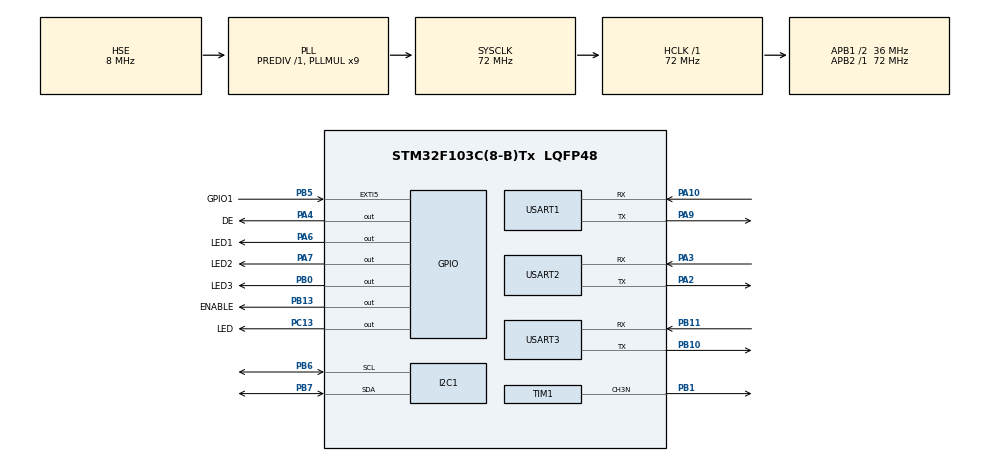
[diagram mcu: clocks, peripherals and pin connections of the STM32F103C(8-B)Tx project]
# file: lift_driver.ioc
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I2C1.DutyCycle=I2C_DUTYCYCLE_16_9
I2C1.I2C_Mode=I2C_Fast
Mcu.Family=STM32F1
Mcu.Name=STM32F103C(8-B)Tx
Mcu.Package=LQFP48
NVIC.EXTI9_5_IRQn=true\:0\:0\:false\:false\:true\:true\:true
NVIC.PriorityGroup=NVIC_PRIORITYGROUP_4
NVIC.TIM3_IRQn=true\:0\:0\:false\:false\:true\:true\:true
PA10.Mode=Asynchronous
PA10.Signal=USART1_RX
PA13.Mode=Serial_Wire
PA13.Signal=SYS_JTMS-SWDIO
PA14.Mode=Serial_Wire
PA14.Signal=SYS_JTCK-SWCLK
PA2.Mode=Asynchronous
PA2.Signal=USART2_TX
PA3.Mode=Asynchronous
PA3.Signal=USART2_RX
PA4.GPIO_Label=DE
PA4.Signal=GPIO_Output
PA6.GPIO_Label=LED1
PA6.Signal=GPIO_Output
PA7.GPIO_Label=LED2
PA7.Signal=GPIO_Output
PA9.Mode=Asynchronous
PA9.Signal=USART1_TX
PB0.GPIO_Label=LED3
PB0.Signal=GPIO_Output
PB1.Mode=PWM Generation3 CH3N
PB1.Signal=TIM1_CH3N
PB10.Mode=Asynchronous
PB10.Signal=USART3_TX
PB11.Mode=Asynchronous
PB11.Signal=USART3_RX
PB13.GPIO_Label=ENABLE
PB13.Signal=GPIO_Output
PB5.GPIO_Label=GPIO1
PB5.GPIO_ModeDefaultEXTI=GPIO_MODE_IT_FALLING
PB5.GPIO_PuPd=GPIO_PULLUP
PB5.Signal=GPXTI5
PB6.Mode=I2C
PB6.Signal=I2C1_SCL
PB7.Mode=I2C
PB7.Signal=I2C1_SDA
PC13-TAMPER-RTC.GPIO_Label=LED
PC13-TAMPER-RTC.Signal=GPIO_Output
PD0-OSC_IN.Mode=HSE-External-Oscillator
PD0-OSC_IN.Signal=RCC_OSC_IN
PD1-OSC_OUT.Mode=HSE-External-Oscillator
PD1-OSC_OUT.Signal=RCC_OSC_OUT
ProjectManager.HeapSize=0x200
ProjectManager.StackSize=0x400
ProjectManager.TargetToolchain=Makefile
RCC.AHBFreq_Value=72000000
RCC.APB1CLKDivider=RCC_HCLK_DIV2
RCC.APB1Freq_Value=36000000
RCC.APB1TimFreq_Value=72000000
RCC.APB2Freq_Value=72000000
RCC.APB2TimFreq_Value=72000000
RCC.HCLKFreq_Value=72000000
RCC.PLLMUL=RCC_PLL_MUL9
RCC.PLLSourceVirtual=RCC_PLLSOURCE_HSE
RCC.SYSCLKFreq_VALUE=72000000
RCC.SYSCLKSource=RCC_SYSCLKSOURCE_PLLCLK
RCC.USBFreq_Value=72000000
TIM1.Channel-PWM\ Generation3\ CH3N=TIM_CHANNEL_3
TIM1.Period=500
TIM1.Prescaler=100
TIM1.Pulse-PWM\ Generation3\ CH3N=250
TIM1.TIM_MasterOutputTrigger=TIM_TRGO_UPDATE
TIM1.TIM_MasterSlaveMode=TIM_MASTERSLAVEMODE_ENABLE
TIM3.Period=2000
TIM3.Prescaler=1
USART1.VirtualMode=VM_ASYNC
USART2.VirtualMode=VM_ASYNC
USART3.VirtualMode=VM_ASYNC
VP_TIM3_VS_ClockSourceITR.Mode=TriggerSource_ITR0
VP_TIM3_VS_ControllerModeClock.Mode=Clock Mode
board=custom

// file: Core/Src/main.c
/* USER CODE BEGIN Header */
/**
  ******************************************************************************
  * @file           : main.c
  * @brief          : Main program body
  ******************************************************************************
  * @attention
  *
  * <h2><center>&copy; Copyright (c) 2021 STMicroelectronics.
  * All rights reserved.</center></h2>
  *
  * This software component is licensed by ST under BSD 3-Clause license,
  * the "License"; You may not use this file except in compliance with the
  * License. You may obtain a copy of the License at:
  *                        opensource.org/licenses/BSD-3-Clause
  *
  ******************************************************************************
  */
/* USER CODE END Header */
#include "main.h"

I2C_HandleTypeDef hi2c1;

TIM_HandleTypeDef htim1;
TIM_HandleTypeDef htim3;

UART_HandleTypeDef huart1;
UART_HandleTypeDef huart2;
UART_HandleTypeDef huart3;

void SystemClock_Config(void);
static void MX_GPIO_Init(void);
static void MX_USART1_UART_Init(void);
static void MX_USART3_UART_Init(void);
static void MX_I2C1_Init(void);
static void MX_USART2_UART_Init(void);
static void MX_TIM1_Init(void);
static void MX_TIM3_Init(void);

/* USER CODE BEGIN 0 */
int myMain();
/* USER CODE END 0 */

int main(void)
{

  /* MCU Configuration--------------------------------------------------------*/

  /* Reset of all peripherals, Initializes the Flash interface and the Systick. */
  HAL_Init();

  /* Configure the system clock */
  SystemClock_Config();

  /* Initialize all configured peripherals */
  MX_GPIO_Init();
  MX_USART1_UART_Init();
  MX_USART3_UART_Init();
  MX_I2C1_Init();
  MX_USART2_UART_Init();
  MX_TIM1_Init();
  MX_TIM3_Init();
  /* USER CODE BEGIN 2 */
  myMain();

//    HAL_GPIO_TogglePin(LED_GPIO_Port, LED_Pin);
//    HAL_GPIO_TogglePin(LED1_GPIO_Port, LED1_Pin);
//    HAL_GPIO_TogglePin(LED2_GPIO_Port, LED2_Pin);
//    HAL_GPIO_TogglePin(LED3_GPIO_Port, LED3_Pin);
//    uint8_t k [5] = {'0', '1','2', '3', '4'};
//    HAL_UART_Init(&huart1);
  /* USER CODE END 2 */

  /* Infinite loop */
  while (1)
  {

    /* USER CODE BEGIN 3 */
//    HAL_Delay(100);
//      HAL_GPIO_TogglePin(LED_GPIO_Port, LED_Pin);

//       HAL_UART_Transmit(&huart1, k, 5, 100);
  }
  /* USER CODE END 3 */
}

void SystemClock_Config(void)
{
  RCC_OscInitTypeDef RCC_OscInitStruct = {0};
  RCC_ClkInitTypeDef RCC_ClkInitStruct = {0};

  /** Initializes the RCC Oscillators according to the specified parameters
  * in the RCC_OscInitTypeDef structure.
  */
  RCC_OscInitStruct.OscillatorType = RCC_OSCILLATORTYPE_HSE;
  RCC_OscInitStruct.HSEState = RCC_HSE_ON;
  RCC_OscInitStruct.HSEPredivValue = RCC_HSE_PREDIV_DIV1;
  RCC_OscInitStruct.HSIState = RCC_HSI_ON;
  RCC_OscInitStruct.PLL.PLLState = RCC_PLL_ON;
  RCC_OscInitStruct.PLL.PLLSource = RCC_PLLSOURCE_HSE;
  RCC_OscInitStruct.PLL.PLLMUL = RCC_PLL_MUL9;
  if (HAL_RCC_OscConfig(&RCC_OscInitStruct) != HAL_OK)
  {
    Error_Handler();
  }
  /** Initializes the CPU, AHB and APB buses clocks
  */
  RCC_ClkInitStruct.ClockType = RCC_CLOCKTYPE_HCLK|RCC_CLOCKTYPE_SYSCLK
                              |RCC_CLOCKTYPE_PCLK1|RCC_CLOCKTYPE_PCLK2;
  RCC_ClkInitStruct.SYSCLKSource = RCC_SYSCLKSOURCE_PLLCLK;
  RCC_ClkInitStruct.AHBCLKDivider = RCC_SYSCLK_DIV1;
  RCC_ClkInitStruct.APB1CLKDivider = RCC_HCLK_DIV2;
  RCC_ClkInitStruct.APB2CLKDivider = RCC_HCLK_DIV1;

  if (HAL_RCC_ClockConfig(&RCC_ClkInitStruct, FLASH_LATENCY_2) != HAL_OK)
  {
    Error_Handler();
  }
}

static void MX_I2C1_Init(void)
{

  hi2c1.Instance = I2C1;
  hi2c1.Init.ClockSpeed = 400000;
  hi2c1.Init.DutyCycle = I2C_DUTYCYCLE_16_9;
  hi2c1.Init.OwnAddress1 = 0;
  hi2c1.Init.AddressingMode = I2C_ADDRESSINGMODE_7BIT;
  hi2c1.Init.DualAddressMode = I2C_DUALADDRESS_DISABLE;
  hi2c1.Init.OwnAddress2 = 0;
  hi2c1.Init.GeneralCallMode = I2C_GENERALCALL_DISABLE;
  hi2c1.Init.NoStretchMode = I2C_NOSTRETCH_DISABLE;
  if (HAL_I2C_Init(&hi2c1) != HAL_OK)
  {
    Error_Handler();
  }

}

static void MX_TIM1_Init(void)
{

  TIM_MasterConfigTypeDef sMasterConfig = {0};
  TIM_OC_InitTypeDef sConfigOC = {0};
  TIM_BreakDeadTimeConfigTypeDef sBreakDeadTimeConfig = {0};

  htim1.Instance = TIM1;
  htim1.Init.Prescaler = 100;
  htim1.Init.CounterMode = TIM_COUNTERMODE_UP;
  htim1.Init.Period = 500;
  htim1.Init.ClockDivision = TIM_CLOCKDIVISION_DIV1;
  htim1.Init.RepetitionCounter = 0;
  htim1.Init.AutoReloadPreload = TIM_AUTORELOAD_PRELOAD_DISABLE;
  if (HAL_TIM_PWM_Init(&htim1) != HAL_OK)
  {
    Error_Handler();
  }
  sMasterConfig.MasterOutputTrigger = TIM_TRGO_UPDATE;
  sMasterConfig.MasterSlaveMode = TIM_MASTERSLAVEMODE_ENABLE;
  if (HAL_TIMEx_MasterConfigSynchronization(&htim1, &sMasterConfig) != HAL_OK)
  {
    Error_Handler();
  }
  sConfigOC.OCMode = TIM_OCMODE_PWM1;
  sConfigOC.Pulse = 250;
  sConfigOC.OCPolarity = TIM_OCPOLARITY_HIGH;
  sConfigOC.OCNPolarity = TIM_OCNPOLARITY_HIGH;
  sConfigOC.OCFastMode = TIM_OCFAST_DISABLE;
  sConfigOC.OCIdleState = TIM_OCIDLESTATE_RESET;
  sConfigOC.OCNIdleState = TIM_OCNIDLESTATE_RESET;
  if (HAL_TIM_PWM_ConfigChannel(&htim1, &sConfigOC, TIM_CHANNEL_3) != HAL_OK)
  {
    Error_Handler();
  }
  sBreakDeadTimeConfig.OffStateRunMode = TIM_OSSR_DISABLE;
  sBreakDeadTimeConfig.OffStateIDLEMode = TIM_OSSI_DISABLE;
  sBreakDeadTimeConfig.LockLevel = TIM_LOCKLEVEL_OFF;
  sBreakDeadTimeConfig.DeadTime = 0;
  sBreakDeadTimeConfig.BreakState = TIM_BREAK_DISABLE;
  sBreakDeadTimeConfig.BreakPolarity = TIM_BREAKPOLARITY_HIGH;
  sBreakDeadTimeConfig.AutomaticOutput = TIM_AUTOMATICOUTPUT_DISABLE;
  if (HAL_TIMEx_ConfigBreakDeadTime(&htim1, &sBreakDeadTimeConfig) != HAL_OK)
  {
    Error_Handler();
  }
  HAL_TIM_MspPostInit(&htim1);

}

static void MX_TIM3_Init(void)
{

  TIM_SlaveConfigTypeDef sSlaveConfig = {0};
  TIM_MasterConfigTypeDef sMasterConfig = {0};

  htim3.Instance = TIM3;
  htim3.Init.Prescaler = 1;
  htim3.Init.CounterMode = TIM_COUNTERMODE_UP;
  htim3.Init.Period = 2000;
  htim3.Init.ClockDivision = TIM_CLOCKDIVISION_DIV1;
  htim3.Init.AutoReloadPreload = TIM_AUTORELOAD_PRELOAD_DISABLE;
  if (HAL_TIM_Base_Init(&htim3) != HAL_OK)
  {
    Error_Handler();
  }
  sSlaveConfig.SlaveMode = TIM_SLAVEMODE_EXTERNAL1;
  sSlaveConfig.InputTrigger = TIM_TS_ITR0;
  if (HAL_TIM_SlaveConfigSynchro(&htim3, &sSlaveConfig) != HAL_OK)
  {
    Error_Handler();
  }
  sMasterConfig.MasterOutputTrigger = TIM_TRGO_RESET;
  sMasterConfig.MasterSlaveMode = TIM_MASTERSLAVEMODE_DISABLE;
  if (HAL_TIMEx_MasterConfigSynchronization(&htim3, &sMasterConfig) != HAL_OK)
  {
    Error_Handler();
  }

}

static void MX_USART1_UART_Init(void)
{

  huart1.Instance = USART1;
  huart1.Init.BaudRate = 115200;
  huart1.Init.WordLength = UART_WORDLENGTH_8B;
  huart1.Init.StopBits = UART_STOPBITS_1;
  huart1.Init.Parity = UART_PARITY_NONE;
  huart1.Init.Mode = UART_MODE_TX_RX;
  huart1.Init.HwFlowCtl = UART_HWCONTROL_NONE;
  huart1.Init.OverSampling = UART_OVERSAMPLING_16;
  if (HAL_UART_Init(&huart1) != HAL_OK)
  {
    Error_Handler();
  }

}

static void MX_USART2_UART_Init(void)
{

  huart2.Instance = USART2;
  huart2.Init.BaudRate = 115200;
  huart2.Init.WordLength = UART_WORDLENGTH_8B;
  huart2.Init.StopBits = UART_STOPBITS_1;
  huart2.Init.Parity = UART_PARITY_NONE;
  huart2.Init.Mode = UART_MODE_TX_RX;
  huart2.Init.HwFlowCtl = UART_HWCONTROL_NONE;
  huart2.Init.OverSampling = UART_OVERSAMPLING_16;
  if (HAL_UART_Init(&huart2) != HAL_OK)
  {
    Error_Handler();
  }

}

static void MX_USART3_UART_Init(void)
{

  huart3.Instance = USART3;
  huart3.Init.BaudRate = 115200;
  huart3.Init.WordLength = UART_WORDLENGTH_8B;
  huart3.Init.StopBits = UART_STOPBITS_1;
  huart3.Init.Parity = UART_PARITY_NONE;
  huart3.Init.Mode = UART_MODE_TX_RX;
  huart3.Init.HwFlowCtl = UART_HWCONTROL_NONE;
  huart3.Init.OverSampling = UART_OVERSAMPLING_16;
  if (HAL_UART_Init(&huart3) != HAL_OK)
  {
    Error_Handler();
  }

}

static void MX_GPIO_Init(void)
{
  GPIO_InitTypeDef GPIO_InitStruct = {0};

  /* GPIO Ports Clock Enable */
  __HAL_RCC_GPIOC_CLK_ENABLE();
  __HAL_RCC_GPIOD_CLK_ENABLE();
  __HAL_RCC_GPIOA_CLK_ENABLE();
  __HAL_RCC_GPIOB_CLK_ENABLE();

  /*Configure GPIO pin Output Level */
  HAL_GPIO_WritePin(LED_GPIO_Port, LED_Pin, GPIO_PIN_RESET);

  /*Configure GPIO pin Output Level */
  HAL_GPIO_WritePin(GPIOA, DE_Pin|LED1_Pin|LED2_Pin, GPIO_PIN_RESET);

  /*Configure GPIO pin Output Level */
  HAL_GPIO_WritePin(GPIOB, LED3_Pin|ENABLE_Pin, GPIO_PIN_RESET);

  /*Configure GPIO pin : LED_Pin */
  GPIO_InitStruct.Pin = LED_Pin;
  GPIO_InitStruct.Mode = GPIO_MODE_OUTPUT_PP;
  GPIO_InitStruct.Pull = GPIO_NOPULL;
  GPIO_InitStruct.Speed = GPIO_SPEED_FREQ_LOW;
  HAL_GPIO_Init(LED_GPIO_Port, &GPIO_InitStruct);

  /*Configure GPIO pins : DE_Pin LED1_Pin LED2_Pin */
  GPIO_InitStruct.Pin = DE_Pin|LED1_Pin|LED2_Pin;
  GPIO_InitStruct.Mode = GPIO_MODE_OUTPUT_PP;
  GPIO_InitStruct.Pull = GPIO_NOPULL;
  GPIO_InitStruct.Speed = GPIO_SPEED_FREQ_LOW;
  HAL_GPIO_Init(GPIOA, &GPIO_InitStruct);

  /*Configure GPIO pins : LED3_Pin ENABLE_Pin */
  GPIO_InitStruct.Pin = LED3_Pin|ENABLE_Pin;
  GPIO_InitStruct.Mode = GPIO_MODE_OUTPUT_PP;
  GPIO_InitStruct.Pull = GPIO_NOPULL;
  GPIO_InitStruct.Speed = GPIO_SPEED_FREQ_LOW;
  HAL_GPIO_Init(GPIOB, &GPIO_InitStruct);

  /*Configure GPIO pin : GPIO1_Pin */
  GPIO_InitStruct.Pin = GPIO1_Pin;
  GPIO_InitStruct.Mode = GPIO_MODE_IT_FALLING;
  GPIO_InitStruct.Pull = GPIO_PULLUP;
  HAL_GPIO_Init(GPIO1_GPIO_Port, &GPIO_InitStruct);

  /* EXTI interrupt init*/
  HAL_NVIC_SetPriority(EXTI9_5_IRQn, 0, 0);
  HAL_NVIC_EnableIRQ(EXTI9_5_IRQn);

}

void Error_Handler(void)
{
}

/************************ (C) COPYRIGHT STMicroelectronics *****END OF FILE****/
